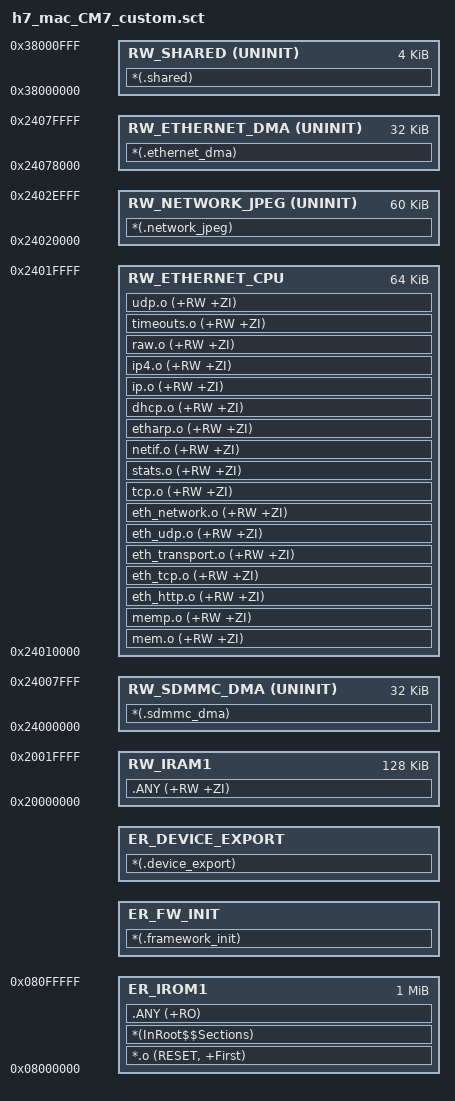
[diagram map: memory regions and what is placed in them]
LR_IROM1 0x08000000 0x00100000
{
    ER_IROM1 0x08000000 0x00100000
    {
        *.o (RESET, +First)
        *(InRoot$$Sections)
        .ANY (+RO)
    }

    ER_FW_INIT +0
    {
        *(.framework_init)
    }

   ER_DEVICE_EXPORT +0
   {
        *(.device_export)
    }

    RW_SHARED 0x38000000 UNINIT 0x00001000
    {
        *(.shared)
    }

    RW_SDMMC_DMA 0x24000000 UNINIT 0x00008000
    {
        *(.sdmmc_dma)
    }

    RW_ETHERNET_DMA 0x24078000 UNINIT 0x00008000
    {
        *(.ethernet_dma)
    }

    RW_ETHERNET_CPU 0x24010000 0x00010000
    {
        mem.o (+RW +ZI)
        memp.o (+RW +ZI)
        eth_http.o (+RW +ZI)
        eth_tcp.o (+RW +ZI)
        eth_transport.o (+RW +ZI)
        eth_udp.o (+RW +ZI)
        eth_network.o (+RW +ZI)
        tcp.o (+RW +ZI)
        stats.o (+RW +ZI)
        netif.o (+RW +ZI)
        etharp.o (+RW +ZI)
        dhcp.o (+RW +ZI)
        ip.o (+RW +ZI)
        ip4.o (+RW +ZI)
        raw.o (+RW +ZI)
        timeouts.o (+RW +ZI)
        udp.o (+RW +ZI)
    }

    RW_NETWORK_JPEG 0x24020000 UNINIT 0x0000F000
    {
        *(.network_jpeg)
    }

    RW_IRAM1 0x20000000 0x00020000
    {
        .ANY (+RW +ZI)
    }
}
